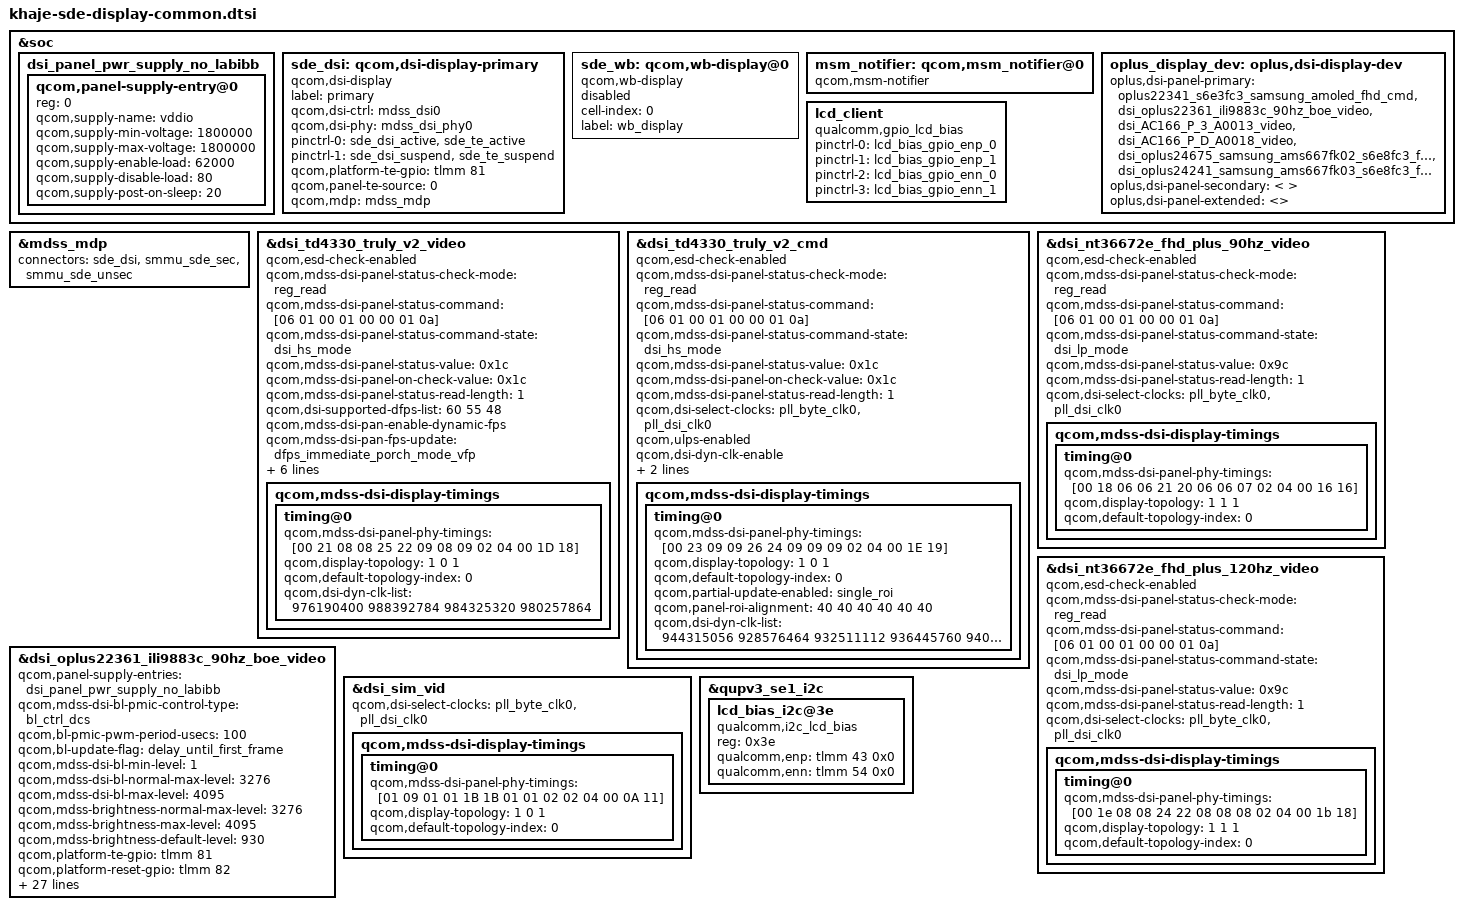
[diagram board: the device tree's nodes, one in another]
#include "dsi-panel-td4330-truly-v2-singlemipi-fhd-cmd.dtsi"
#include "dsi-panel-td4330-truly-v2-singlemipi-fhd-vid.dtsi"
#include "dsi-panel-nt36672e-fhd-plus-90hz-video.dtsi"
#include "dsi-panel-nt36672e-fhd-plus-120hz-video.dtsi"
#include "dsi-panel-oplus-samsung-s6e3fc3-1080-2400-dsi-cmd.dtsi"
#include "dsi-panel-sim-video.dtsi"
#include "dts-panel-oplus22361-boe-ili9883c-video.dtsi"
#include "dsi-panel-AC166-P-3-A0013-720-1604-video.dtsi"
#include "dsi-panel-AC166-P-D-A0018-720-1604-video.dtsi"
#include "avatar-sde-display-pinctrl.dtsi"
#include "dsi-panel-oplus24675-samsung-ams667fk02-s6e8fc3-fhdp-vid.dtsi"
#include "dsi-panel-oplus-samsung-s6e8fc3-1080-2400-dsi-vid.dtsi"
&soc {
	dsi_panel_pwr_supply_no_labibb: dsi_panel_pwr_supply_no_labibb {
		#address-cells = <1>;
		#size-cells = <0>;

		qcom,panel-supply-entry@0 {
			reg = <0>;
			qcom,supply-name = "vddio";
			qcom,supply-min-voltage = <1800000>;
			qcom,supply-max-voltage = <1800000>;
			qcom,supply-enable-load = <62000>;
			qcom,supply-disable-load = <80>;
			qcom,supply-post-on-sleep = <20>;
		};
	};

	sde_dsi: qcom,dsi-display-primary {
		compatible = "qcom,dsi-display";
		label = "primary";
		qcom,dsi-ctrl = <&mdss_dsi0>;
		qcom,dsi-phy = <&mdss_dsi_phy0>;

		pinctrl-names = "panel_active", "panel_suspend";
		pinctrl-0 = <&sde_dsi_active &sde_te_active>;
		pinctrl-1 = <&sde_dsi_suspend &sde_te_suspend>;

		qcom,platform-te-gpio = <&tlmm 81 0>;
		qcom,panel-te-source = <0>;

		qcom,mdp = <&mdss_mdp>;

	};

	sde_wb: qcom,wb-display@0 {
		status = "disabled";
		compatible = "qcom,wb-display";
		cell-index = <0>;
		label = "wb_display";
	};

	msm_notifier: qcom,msm_notifier@0 {
		compatible = "qcom,msm-notifier";
	};

	oplus_display_dev: oplus,dsi-display-dev {
		oplus,dsi-panel-primary = <
			&oplus22341_s6e3fc3_samsung_amoled_fhd_cmd
			&dsi_oplus22361_ili9883c_90hz_boe_video
			&dsi_AC166_P_3_A0013_video
			&dsi_AC166_P_D_A0018_video
			&dsi_oplus24675_samsung_ams667fk02_s6e8fc3_fhdp_vid
			&dsi_oplus24241_samsung_ams667fk03_s6e8fc3_fhdp_vid
		>;
		oplus,dsi-panel-secondary = <
		>;
		oplus,dsi-panel-extended = <>;
	};

};

&mdss_mdp {
	connectors = <&sde_dsi &smmu_sde_sec &smmu_sde_unsec>;
};

&dsi_td4330_truly_v2_video {
	qcom,esd-check-enabled;
	qcom,mdss-dsi-panel-status-check-mode = "reg_read";
	qcom,mdss-dsi-panel-status-command = [06 01 00 01 00 00 01 0a];
	qcom,mdss-dsi-panel-status-command-state = "dsi_hs_mode";
	qcom,mdss-dsi-panel-status-value = <0x1c>;
	qcom,mdss-dsi-panel-on-check-value = <0x1c>;
	qcom,mdss-dsi-panel-status-read-length = <1>;
	qcom,dsi-supported-dfps-list = <60 55 48>;
	qcom,mdss-dsi-pan-enable-dynamic-fps;
	qcom,mdss-dsi-pan-fps-update =
			"dfps_immediate_porch_mode_vfp";
        qcom,dsi-select-clocks = "pll_byte_clk0", "pll_dsi_clk0";
	qcom,dsi-dyn-clk-enable;
	qcom,dsi-dyn-clk-type = "constant-fps-adjust-vfp";
	qcom,dsi-dyn-clk-list =
			<976190400 988392784 984325320 980257864>;
	qcom,mdss-dsi-display-timings {
		timing@0 {
			qcom,mdss-dsi-panel-phy-timings = [00 21 08 08 25 22 09
					08 09 02 04 00 1D 18];
			qcom,display-topology = <1 0 1>;
			qcom,default-topology-index = <0>;
			qcom,dsi-dyn-clk-list =
				<976190400 988392784 984325320 980257864>;
		};
	};
};

&dsi_td4330_truly_v2_cmd {
	qcom,esd-check-enabled;
	qcom,mdss-dsi-panel-status-check-mode = "reg_read";
	qcom,mdss-dsi-panel-status-command = [06 01 00 01 00 00 01 0a];
	qcom,mdss-dsi-panel-status-command-state = "dsi_hs_mode";
	qcom,mdss-dsi-panel-status-value = <0x1c>;
	qcom,mdss-dsi-panel-on-check-value = <0x1c>;
	qcom,mdss-dsi-panel-status-read-length = <1>;
        qcom,dsi-select-clocks = "pll_byte_clk0", "pll_dsi_clk0";
	qcom,ulps-enabled;
	qcom,dsi-dyn-clk-enable;
	qcom,dsi-dyn-clk-list =
		<944315056 928576464 932511112 936445760 940380400>;
	qcom,mdss-dsi-display-timings {
		timing@0 {
			qcom,mdss-dsi-panel-phy-timings = [00 23 09 09 26 24 09
					09 09 02 04 00 1E 19];
			qcom,display-topology = <1 0 1>;
			qcom,default-topology-index = <0>;
			qcom,partial-update-enabled = "single_roi";
			qcom,panel-roi-alignment = <40 40 40 40 40 40>;
			qcom,dsi-dyn-clk-list =
				<944315056 928576464 932511112 936445760 940380400>;
		};
	};
};

&dsi_nt36672e_fhd_plus_90hz_video {
	qcom,esd-check-enabled;
	qcom,mdss-dsi-panel-status-check-mode = "reg_read";
	qcom,mdss-dsi-panel-status-command = [06 01 00 01 00 00 01 0a];
	qcom,mdss-dsi-panel-status-command-state = "dsi_lp_mode";
	qcom,mdss-dsi-panel-status-value = <0x9c>;
	qcom,mdss-dsi-panel-status-read-length = <1>;
        qcom,dsi-select-clocks = "pll_byte_clk0", "pll_dsi_clk0";
	qcom,mdss-dsi-display-timings {
		timing@0 {
			qcom,mdss-dsi-panel-phy-timings = [00 18 06 06 21 20 06
					06 07 02 04 00 16 16];
			qcom,display-topology = <1 1 1>;
			qcom,default-topology-index = <0>;
		};
	};
};

&dsi_nt36672e_fhd_plus_120hz_video {
	qcom,esd-check-enabled;
	qcom,mdss-dsi-panel-status-check-mode = "reg_read";
	qcom,mdss-dsi-panel-status-command = [06 01 00 01 00 00 01 0a];
	qcom,mdss-dsi-panel-status-command-state = "dsi_lp_mode";
	qcom,mdss-dsi-panel-status-value = <0x9c>;
	qcom,mdss-dsi-panel-status-read-length = <1>;
        qcom,dsi-select-clocks = "pll_byte_clk0", "pll_dsi_clk0";
	qcom,mdss-dsi-display-timings {
		timing@0 {
			qcom,mdss-dsi-panel-phy-timings = [00 1e 08 08 24 22 08
					08 08 02 04 00 1b 18];
			qcom,display-topology = <1 1 1>;
			qcom,default-topology-index = <0>;
		};
	};
};

&dsi_oplus22361_ili9883c_90hz_boe_video {
	qcom,panel-supply-entries = <&dsi_panel_pwr_supply_no_labibb>;
	qcom,mdss-dsi-bl-pmic-control-type = "bl_ctrl_dcs";
	qcom,bl-pmic-pwm-period-usecs = <100>;
	qcom,bl-update-flag = "delay_until_first_frame";
	qcom,mdss-dsi-bl-min-level = <1>;
	qcom,mdss-dsi-bl-normal-max-level = <3276>;
	qcom,mdss-dsi-bl-max-level = <4095>;
	qcom,mdss-brightness-normal-max-level = <3276>;
	qcom,mdss-brightness-max-level = <4095>;
	qcom,mdss-brightness-default-level = <930>;
	qcom,platform-te-gpio = <&tlmm 81 0>;
	qcom,platform-reset-gpio = <&tlmm 82 0>;
	qcom,platform-panel-P5V-gpio = <&tlmm 43 0>;
	qcom,platform-panel-N5V-gpio = <&tlmm 54 0>;
	qcom,platform-panel-vddi-gpio = <&tlmm 103 0>;
	oplus,mdss-dsi-vspn-voltage = <6000>;
	oplus,mdss-dsi-gamma-switch-enabled;
	qcom,mdss-dsi-t-clk-post = <0x0D>;
	qcom,mdss-dsi-t-clk-pre = <0x2D>;
	qcom,dsi-supported-dfps-list = <60 90>;
	qcom,mdss-dsi-pan-enable-dynamic-fps;
	qcom,mdss-dsi-pan-fps-update =
		"dfps_immediate_porch_mode_vfp";
	qcom,mdss-dsi-min-refresh-rate = <60>;
	qcom,mdss-dsi-max-refresh-rate = <90>;
	oplus,dfps-idle-off;
	qcom,esd-check-enabled;
	qcom,mdss-dsi-panel-status-check-mode = "reg_read";
	qcom,mdss-dsi-panel-status-command = [06 01 00 01 00 00 01 0A];
	qcom,mdss-dsi-panel-status-command-state = "dsi_lp_mode";
	qcom,mdss-dsi-panel-status-value = <0x9c>;
	//qcom,mdss-dsi-panel-on-check-value = <0x9c>;
	qcom,mdss-dsi-panel-status-read-length = <1>;
	qcom,dsi-select-clocks = "mux_byte_clk0", "mux_pixel_clk0",
				"src_byte_clk0", "src_pixel_clk0",
				"shadow_byte_clk0", "shadow_pixel_clk0";
};

&dsi_sim_vid {
        qcom,dsi-select-clocks = "pll_byte_clk0", "pll_dsi_clk0";
	qcom,mdss-dsi-display-timings {
		timing@0 {
			qcom,mdss-dsi-panel-phy-timings = [01 09 01 01 1B 1B 01
					01 02 02 04 00 0A 11];
			qcom,display-topology = <1 0 1>;
			qcom,default-topology-index = <0>;
		};
	};
};

/* #ifdef OPLUS_FEATURE_DISPLAY */
&qupv3_se1_i2c {
	#address-cells = <1>;
	#size-cells = <0>;

	status = "okay";

	lcd_bias_i2c@3e {
		compatible = "qualcomm,i2c_lcd_bias";
		reg = <0x3e>;
		qualcomm,enp = <&tlmm 43 0x0>;
		qualcomm,enn = <&tlmm 54 0x0>;
		status = "okay";
	};
};

&soc {
	lcd_client {
		compatible = "qualcomm,gpio_lcd_bias";
		pinctrl-names = "lcd_bias_gpio_enp0","lcd_bias_gpio_enp1","lcd_bias_gpio_enn0","lcd_bias_gpio_enn1";
		pinctrl-0 = <&lcd_bias_gpio_enp_0>;
		pinctrl-1 = <&lcd_bias_gpio_enp_1>;
		pinctrl-2 = <&lcd_bias_gpio_enn_0>;
		pinctrl-3 = <&lcd_bias_gpio_enn_1>;
		status = "okay";
	};
};
/* #endif */

